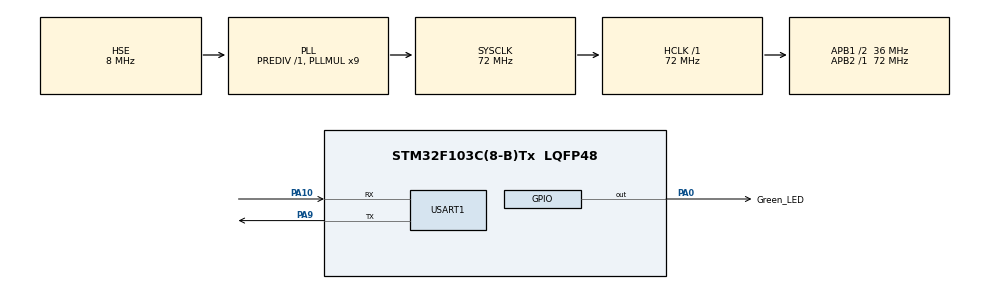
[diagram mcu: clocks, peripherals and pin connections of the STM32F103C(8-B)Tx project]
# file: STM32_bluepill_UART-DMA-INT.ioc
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Dma.Request0=USART1_TX
Dma.USART1_TX.0.Direction=DMA_MEMORY_TO_PERIPH
Dma.USART1_TX.0.Instance=DMA1_Channel4
Dma.USART1_TX.0.MemDataAlignment=DMA_MDATAALIGN_BYTE
Dma.USART1_TX.0.MemInc=DMA_MINC_ENABLE
Dma.USART1_TX.0.Mode=DMA_CIRCULAR
Dma.USART1_TX.0.PeriphDataAlignment=DMA_PDATAALIGN_BYTE
Dma.USART1_TX.0.PeriphInc=DMA_PINC_DISABLE
Dma.USART1_TX.0.Priority=DMA_PRIORITY_LOW
Mcu.Family=STM32F1
Mcu.Name=STM32F103C(8-B)Tx
Mcu.Package=LQFP48
NVIC.DMA1_Channel4_IRQn=true\:0\:0\:false\:false\:true\:false\:true\:true
NVIC.PriorityGroup=NVIC_PRIORITYGROUP_4
NVIC.USART1_IRQn=true\:0\:0\:false\:false\:true\:true\:true\:true
PA0-WKUP.GPIO_Label=Green_LED
PA0-WKUP.Signal=GPIO_Output
PA10.Mode=Asynchronous
PA10.Signal=USART1_RX
PA13.Mode=Serial_Wire
PA13.Signal=SYS_JTMS-SWDIO
PA14.Mode=Serial_Wire
PA14.Signal=SYS_JTCK-SWCLK
PA9.Mode=Asynchronous
PA9.Signal=USART1_TX
PD0-OSC_IN.Mode=HSE-External-Oscillator
PD0-OSC_IN.Signal=RCC_OSC_IN
PD1-OSC_OUT.Mode=HSE-External-Oscillator
PD1-OSC_OUT.Signal=RCC_OSC_OUT
ProjectManager.HeapSize=0x200
ProjectManager.StackSize=0x400
ProjectManager.TargetToolchain=CMake
RCC.AHBFreq_Value=72000000
RCC.APB1CLKDivider=RCC_HCLK_DIV2
RCC.APB1Freq_Value=36000000
RCC.APB1TimFreq_Value=72000000
RCC.APB2Freq_Value=72000000
RCC.APB2TimFreq_Value=72000000
RCC.HCLKFreq_Value=72000000
RCC.PLLMUL=RCC_PLL_MUL9
RCC.PLLSourceVirtual=RCC_PLLSOURCE_HSE
RCC.SYSCLKFreq_VALUE=72000000
RCC.SYSCLKSource=RCC_SYSCLKSOURCE_PLLCLK
RCC.USBFreq_Value=72000000
USART1.VirtualMode=VM_ASYNC
board=custom

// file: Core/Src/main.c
/* USER CODE BEGIN Header */
/**
  ******************************************************************************
  * @file           : main.c
  * @brief          : Main program body
  ******************************************************************************
  * @attention
  *
  * Copyright (c) 2025 STMicroelectronics.
  * All rights reserved.
  *
  * This software is licensed under terms that can be found in the LICENSE file
  * in the root directory of this software component.
  * If no LICENSE file comes with this software, it is provided AS-IS.
  *
  ******************************************************************************
  */
/* USER CODE END Header */
#include "main.h"

UART_HandleTypeDef huart1;
DMA_HandleTypeDef hdma_usart1_tx;

void SystemClock_Config(void);
static void MX_GPIO_Init(void);
static void MX_DMA_Init(void);
static void MX_USART1_UART_Init(void);

/* USER CODE BEGIN 0 */
uint8_t TxData[10240];
uint8_t isSent = 1; // Flag to indicate if data has been sent
int sendCounter = 0; // Counter to keep track of the number of times data has been sent
int loopCounter = 0; // Counter to keep track of the number of times the loop has run
int maxSend = 1024 * 100; // Size of the TxData send total
int currentSend = 0; // Current size of the TxData send

void HAL_UART_TxHalfCpltCallback(UART_HandleTypeDef *huart)
{
  for (int i = 0; i < (int)sizeof(TxData) / 2; i++)
  {
    TxData[i] = i % 256;
  }
  currentSend += sizeof(TxData) / 2; // Update the current send size
}
void HAL_UART_TxCpltCallback(UART_HandleTypeDef *huart)
{
  for (int i = (int)sizeof(TxData) / 2; i < (int)sizeof(TxData); i++)
  {
    TxData[i] = i % 256;
  }
  currentSend += sizeof(TxData) / 2; // Update the current send size
  isSent = 1; // Reset the flag to indicate that data can be sent again

  if (currentSend >= maxSend) // Check if the maximum send size has been reached
  {
    HAL_UART_DMAStop(&huart1); // Stop the DMA transfer
  }
}

/* USER CODE END 0 */

int main(void)
{

  /* MCU Configuration--------------------------------------------------------*/

  /* Reset of all peripherals, Initializes the Flash interface and the Systick. */
  HAL_Init();

  /* Configure the system clock */
  SystemClock_Config();

  /* Initialize all configured peripherals */
  MX_GPIO_Init();
  MX_DMA_Init();
  MX_USART1_UART_Init();
  /* USER CODE BEGIN 2 */
  HAL_UART_Init(&huart1); // Initialize the UART peripheral
  for (int i = 0; i < (int)sizeof(TxData); i++)
  {
    TxData[i] = i % 256;
  }

  HAL_UART_Transmit_DMA(&huart1, TxData, sizeof(TxData)); // Start the DMA transfer

  /* USER CODE END 2 */

  /* Infinite loop */
  while (1)
  {

    /* USER CODE BEGIN 3 */
    // HAL_UART_Transmit(&huart1, TxData, sizeof(TxData), 1000);
    // if (isSent == 0)
    // {
    //   HAL_UART_Transmit_IT(&huart1, TxData, sizeof(TxData));

    //   isSent = 1;
    // }

    // if (isSent == 1) // Check if data has not been sent yet
    // {
    //   HAL_UART_Transmit_DMA(&huart1, TxData, sizeof(TxData)); // Send data using DMA
    //   isSent = 1; // Set the flag to indicate that data has been sent
    // }

    HAL_GPIO_TogglePin(Green_LED_GPIO_Port, Green_LED_Pin);
    loopCounter++; // Increment the loop counter
    HAL_Delay(500); // Delay to avoid flooding the UART
  }
  /* USER CODE END 3 */
}

void SystemClock_Config(void)
{
  RCC_OscInitTypeDef RCC_OscInitStruct = {0};
  RCC_ClkInitTypeDef RCC_ClkInitStruct = {0};

  /** Initializes the RCC Oscillators according to the specified parameters
  * in the RCC_OscInitTypeDef structure.
  */
  RCC_OscInitStruct.OscillatorType = RCC_OSCILLATORTYPE_HSE;
  RCC_OscInitStruct.HSEState = RCC_HSE_ON;
  RCC_OscInitStruct.HSEPredivValue = RCC_HSE_PREDIV_DIV1;
  RCC_OscInitStruct.HSIState = RCC_HSI_ON;
  RCC_OscInitStruct.PLL.PLLState = RCC_PLL_ON;
  RCC_OscInitStruct.PLL.PLLSource = RCC_PLLSOURCE_HSE;
  RCC_OscInitStruct.PLL.PLLMUL = RCC_PLL_MUL9;
  if (HAL_RCC_OscConfig(&RCC_OscInitStruct) != HAL_OK)
  {
    Error_Handler();
  }

  /** Initializes the CPU, AHB and APB buses clocks
  */
  RCC_ClkInitStruct.ClockType = RCC_CLOCKTYPE_HCLK|RCC_CLOCKTYPE_SYSCLK
                              |RCC_CLOCKTYPE_PCLK1|RCC_CLOCKTYPE_PCLK2;
  RCC_ClkInitStruct.SYSCLKSource = RCC_SYSCLKSOURCE_PLLCLK;
  RCC_ClkInitStruct.AHBCLKDivider = RCC_SYSCLK_DIV1;
  RCC_ClkInitStruct.APB1CLKDivider = RCC_HCLK_DIV2;
  RCC_ClkInitStruct.APB2CLKDivider = RCC_HCLK_DIV1;

  if (HAL_RCC_ClockConfig(&RCC_ClkInitStruct, FLASH_LATENCY_2) != HAL_OK)
  {
    Error_Handler();
  }
}

static void MX_USART1_UART_Init(void)
{

  huart1.Instance = USART1;
  huart1.Init.BaudRate = 115200;
  huart1.Init.WordLength = UART_WORDLENGTH_8B;
  huart1.Init.StopBits = UART_STOPBITS_1;
  huart1.Init.Parity = UART_PARITY_NONE;
  huart1.Init.Mode = UART_MODE_TX_RX;
  huart1.Init.HwFlowCtl = UART_HWCONTROL_NONE;
  huart1.Init.OverSampling = UART_OVERSAMPLING_16;
  if (HAL_UART_Init(&huart1) != HAL_OK)
  {
    Error_Handler();
  }

}

static void MX_DMA_Init(void)
{

  /* DMA controller clock enable */
  __HAL_RCC_DMA1_CLK_ENABLE();

  /* DMA interrupt init */
  /* DMA1_Channel4_IRQn interrupt configuration */
  HAL_NVIC_SetPriority(DMA1_Channel4_IRQn, 0, 0);
  HAL_NVIC_EnableIRQ(DMA1_Channel4_IRQn);

}

static void MX_GPIO_Init(void)
{
  GPIO_InitTypeDef GPIO_InitStruct = {0};

  /* GPIO Ports Clock Enable */
  __HAL_RCC_GPIOD_CLK_ENABLE();
  __HAL_RCC_GPIOA_CLK_ENABLE();

  /*Configure GPIO pin Output Level */
  HAL_GPIO_WritePin(Green_LED_GPIO_Port, Green_LED_Pin, GPIO_PIN_RESET);

  /*Configure GPIO pin : Green_LED_Pin */
  GPIO_InitStruct.Pin = Green_LED_Pin;
  GPIO_InitStruct.Mode = GPIO_MODE_OUTPUT_PP;
  GPIO_InitStruct.Pull = GPIO_NOPULL;
  GPIO_InitStruct.Speed = GPIO_SPEED_FREQ_LOW;
  HAL_GPIO_Init(Green_LED_GPIO_Port, &GPIO_InitStruct);

}

void Error_Handler(void)
{
  __disable_irq();
  while (1)
  {
  }
}
